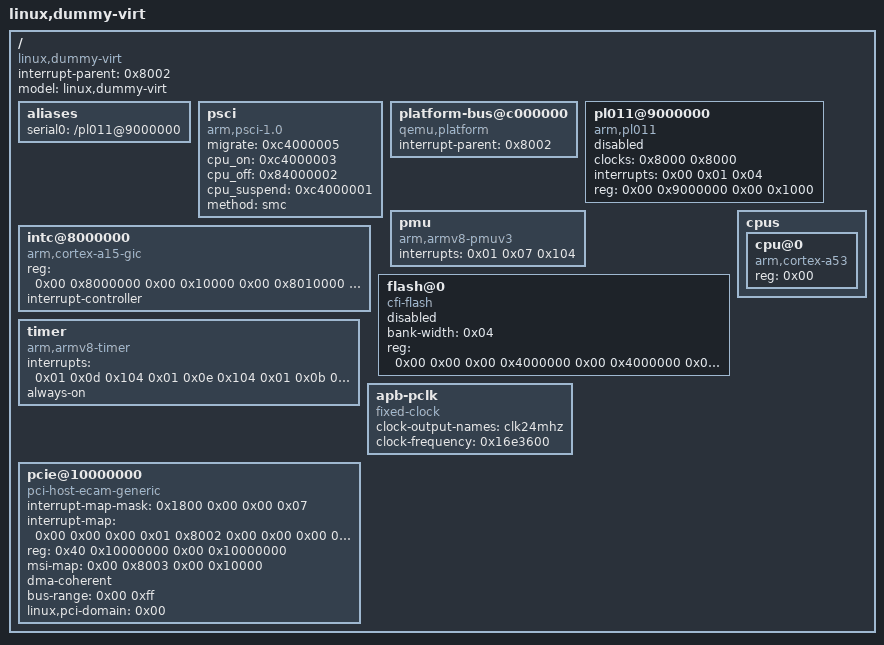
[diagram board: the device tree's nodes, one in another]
/dts-v1/;

/ {
	interrupt-parent = <0x8002>;
	model = "linux,dummy-virt";
	#size-cells = <0x02>;
	#address-cells = <0x02>;
	compatible = "linux,dummy-virt";

	aliases {
		serial0 = "/pl011@9000000";
	};

	psci {
		migrate = <0xc4000005>;
		cpu_on = <0xc4000003>;
		cpu_off = <0x84000002>;
		cpu_suspend = <0xc4000001>;
		method = "smc";
		compatible = "arm,psci-1.0\0arm,psci-0.2\0arm,psci";
	};

	platform-bus@c000000 {
		interrupt-parent = <0x8002>;
		ranges = <0x00 0x00 0xc000000 0x2000000>;
		#address-cells = <0x01>;
		#size-cells = <0x01>;
		compatible = "qemu,platform\0simple-bus";
	};

	pl011@9000000 {
		clock-names = "uartclk\0apb_pclk";
		clocks = <0x8000 0x8000>;
		interrupts = <0x00 0x01 0x04>;
		reg = <0x00 0x9000000 0x00 0x1000>;
		compatible = "arm,pl011\0arm,primecell";
		status = "disabled";
	};

	pmu {
		interrupts = <0x01 0x07 0x104>;
		compatible = "arm,armv8-pmuv3";
	};

	intc@8000000 {
		phandle = <0x8002>;
		reg = <0x00 0x8000000 0x00 0x10000 0x00 0x8010000 0x00 0x10000>;
		compatible = "arm,cortex-a15-gic";
		ranges;
		#size-cells = <0x02>;
		#address-cells = <0x02>;
		interrupt-controller;
		#interrupt-cells = <0x03>;
	};

	flash@0 {
		bank-width = <0x04>;
		reg = <0x00 0x00 0x00 0x4000000 0x00 0x4000000 0x00 0x4000000>;
		compatible = "cfi-flash";
		status = "disabled";
	};

	cpus {
		#size-cells = <0x00>;
		#address-cells = <0x01>;

		cpu@0 {
			phandle = <0x8001>;
			reg = <0x00>;
			compatible = "arm,cortex-a53";
			device_type = "cpu";
		};
	};

	timer {
		interrupts = <0x01 0x0d 0x104 0x01 0x0e 0x104 0x01 0x0b 0x104 0x01 0x0a 0x104>;
		always-on;
		compatible = "arm,armv8-timer\0arm,armv7-timer";
	};

	apb-pclk {
		phandle = <0x8000>;
		clock-output-names = "clk24mhz";
		clock-frequency = <0x16e3600>;
		#clock-cells = <0x00>;
		compatible = "fixed-clock";
	};

    pcie@10000000 {
		interrupt-map-mask = <0x1800 0x00 0x00 0x07>;
		interrupt-map = <0x00 0x00 0x00 0x01 0x8002 0x00 0x00 0x00 0x03 0x04 0x00 0x00 0x00 0x02 0x8002 0x00 0x00 0x00 0x04 0x04 0x00 0x00 0x00 0x03 0x8002 0x00 0x00 0x00 0x05 0x04 0x00 0x00 0x00 0x04 0x8002 0x00 0x00 0x00 0x06 0x04 0x800 0x00 0x00 0x01 0x8002 0x00 0x00 0x00 0x04 0x04 0x800 0x00 0x00 0x02 0x8002 0x00 0x00 0x00 0x05 0x04 0x800 0x00 0x00 0x03 0x8002 0x00 0x00 0x00 0x06 0x04 0x800 0x00 0x00 0x04 0x8002 0x00 0x00 0x00 0x03 0x04 0x1000 0x00 0x00 0x01 0x8002 0x00 0x00 0x00 0x05 0x04 0x1000 0x00 0x00 0x02 0x8002 0x00 0x00 0x00 0x06 0x04 0x1000 0x00 0x00 0x03 0x8002 0x00 0x00 0x00 0x03 0x04 0x1000 0x00 0x00 0x04 0x8002 0x00 0x00 0x00 0x04 0x04 0x1800 0x00 0x00 0x01 0x8002 0x00 0x00 0x00 0x06 0x04 0x1800 0x00 0x00 0x02 0x8002 0x00 0x00 0x00 0x03 0x04 0x1800 0x00 0x00 0x03 0x8002 0x00 0x00 0x00 0x04 0x04 0x1800 0x00 0x00 0x04 0x8002 0x00 0x00 0x00 0x05 0x04>;
		#interrupt-cells = <0x01>;
		//        BUS_ADDRESS                     CPU BUS ADDRESS   Size of segment
		ranges = <0x1000000 0x00 0x00             0x00 0x3eff0000   0x00 0x10000
		          0x2000000 0x00 0x10000000       0x00 0x10000000   0x00 0x2eff0000
				  0x3000000 0x80 0x00             0x80 0x00         0x80 0x00>;
		reg = <0x40 0x10000000 0x00 0x10000000>;
		msi-map = <0x00 0x8003 0x00 0x10000>;
		dma-coherent;
		bus-range = <0x00 0xff>;
		linux,pci-domain = <0x00>;
		#size-cells = <0x02>;
		#address-cells = <0x03>;
		device_type = "pci";
		compatible = "pci-host-ecam-generic";
	};
};
